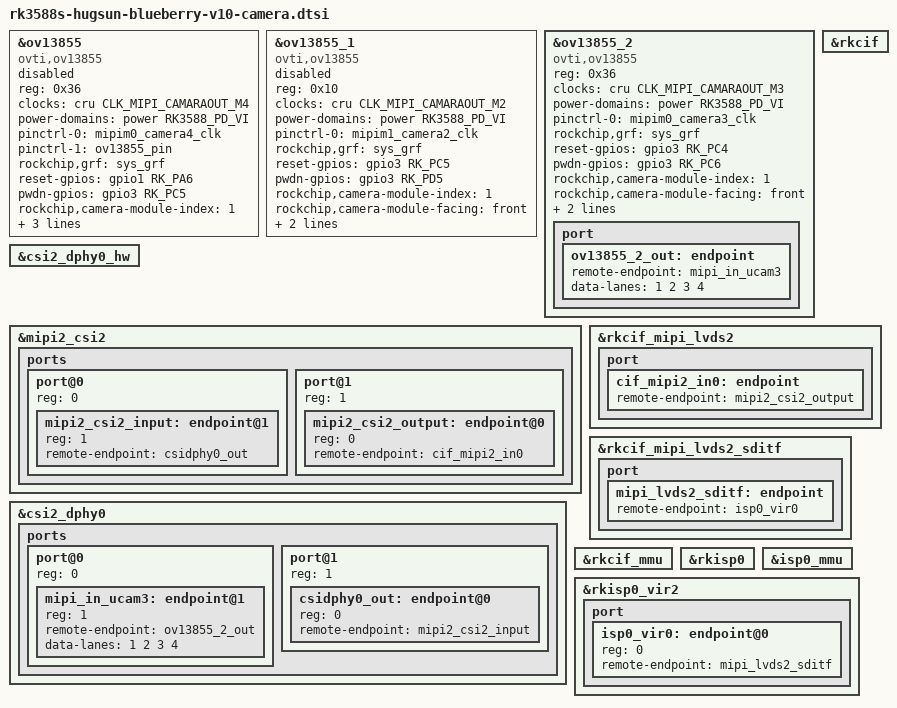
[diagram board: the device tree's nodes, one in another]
// SPDX-License-Identifier: (GPL-2.0+ OR MIT)
/*
 * Copyright (c) 2021 Rockchip Electronics Co., Ltd.
 *
 */

//camera

&ov13855 {
	compatible = "ovti,ov13855";
	status = "disabled";
	reg = <0x36>;
	clocks = <&cru CLK_MIPI_CAMARAOUT_M4>;
	clock-names = "xvclk";
	power-domains = <&power RK3588_PD_VI>;
	pinctrl-names = "default","default";
	pinctrl-0 = <&mipim0_camera4_clk>;
	pinctrl-1 = <&ov13855_pin>;
	rockchip,grf = <&sys_grf>;
	reset-gpios = <&gpio1 RK_PA6 GPIO_ACTIVE_HIGH>;
	pwdn-gpios = <&gpio3 RK_PC5 GPIO_ACTIVE_HIGH>;
	rockchip,camera-module-index = <1>;
	rockchip,camera-module-facing = "front";
	rockchip,camera-module-name = "CMK-OT2016-FV1";
	rockchip,camera-module-lens-name = "default";
};

&ov13855_1 {
		compatible = "ovti,ov13855";
		status = "disabled";
		reg = <0x10>;
		clocks = <&cru CLK_MIPI_CAMARAOUT_M2>;
		clock-names = "xvclk";
		power-domains = <&power RK3588_PD_VI>;
		pinctrl-names = "default";
		pinctrl-0 = <&mipim1_camera2_clk>;
		rockchip,grf = <&sys_grf>;
		reset-gpios = <&gpio3 RK_PC5 GPIO_ACTIVE_HIGH>;
		pwdn-gpios = <&gpio3 RK_PD5 GPIO_ACTIVE_HIGH>;
		rockchip,camera-module-index = <1>;
		rockchip,camera-module-facing = "front";
		rockchip,camera-module-name = "CMK-OT2016-FV1";
		rockchip,camera-module-lens-name = "default";
};

&ov13855_2 {
		compatible = "ovti,ov13855";
		status = "okay";
		reg = <0x36>;
		clocks = <&cru CLK_MIPI_CAMARAOUT_M3>;
		clock-names = "xvclk";
		power-domains = <&power RK3588_PD_VI>;
		pinctrl-names = "default";
		pinctrl-0 = <&mipim0_camera3_clk>;
		rockchip,grf = <&sys_grf>;
		reset-gpios = <&gpio3 RK_PC4 GPIO_ACTIVE_HIGH>;
		pwdn-gpios = <&gpio3 RK_PC6 GPIO_ACTIVE_HIGH>;
		rockchip,camera-module-index = <1>;
		rockchip,camera-module-facing = "front";
		rockchip,camera-module-name = "CMK-OT2016-FV1";
		rockchip,camera-module-lens-name = "default";
		port {
			ov13855_2_out: endpoint {
				remote-endpoint = <&mipi_in_ucam3>;
				data-lanes = <1 2 3 4>;
			};
		};
};

// camera3 start 

&csi2_dphy0_hw {
	status = "okay";
};

&mipi2_csi2 {
	status = "okay";

	ports {
		#address-cells = <1>;
		#size-cells = <0>;

		port@0 {
			reg = <0>;
			#address-cells = <1>;
			#size-cells = <0>;

			mipi2_csi2_input: endpoint@1 {
				reg = <1>;
				remote-endpoint = <&csidphy0_out>;
			};
		};

		port@1 {
			reg = <1>;
			#address-cells = <1>;
			#size-cells = <0>;

			mipi2_csi2_output: endpoint@0 {
				reg = <0>;
				remote-endpoint = <&cif_mipi2_in0>;
			};
		};
	};
};

&csi2_dphy0 {
	status = "okay";

	ports {
		#address-cells = <1>;
		#size-cells = <0>;
		port@0 {
			reg = <0>;
			#address-cells = <1>;
			#size-cells = <0>;

			mipi_in_ucam3: endpoint@1 {
				reg = <1>;
				remote-endpoint = <&ov13855_2_out>;
				data-lanes = <1 2 3 4>;
			};
		};
		port@1 {
			reg = <1>;
			#address-cells = <1>;
			#size-cells = <0>;

			csidphy0_out: endpoint@0 {
				reg = <0>;
				remote-endpoint = <&mipi2_csi2_input>;
			};
		};
	};
};


&rkcif {
	status = "okay";
};

&rkcif_mipi_lvds2 {
	status = "okay";

	port {
		cif_mipi2_in0: endpoint {
			remote-endpoint = <&mipi2_csi2_output>;
		};
	};
};

&rkcif_mipi_lvds2_sditf {
	status = "okay";

	port {
		mipi_lvds2_sditf: endpoint {
			remote-endpoint = <&isp0_vir0>;
		};
	};
};

&rkcif_mmu {
	status = "okay";
};

&rkisp0 {
	status = "okay";
};

&isp0_mmu {
	status = "okay";
};

&rkisp0_vir2 {
	status = "okay";

	port {
		#address-cells = <1>;
		#size-cells = <0>;

		isp0_vir0: endpoint@0 {
			reg = <0>;
			remote-endpoint = <&mipi_lvds2_sditf>;
		};
	};
};
